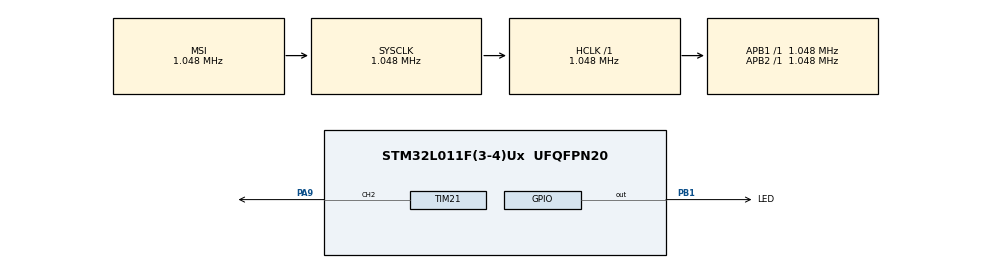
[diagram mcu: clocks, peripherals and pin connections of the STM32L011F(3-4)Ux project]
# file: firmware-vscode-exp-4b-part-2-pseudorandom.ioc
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Mcu.Family=STM32L0
Mcu.Name=STM32L011F(3-4)Ux
Mcu.Package=UFQFPN20
NVIC.TIM21_IRQn=true\:0\:0\:false\:false\:true\:true\:true\:true
NVIC.TIM2_IRQn=true\:0\:0\:false\:false\:true\:true\:true\:true
PA9.Signal=S_TIM21_CH2
PB1.GPIO_Label=LED
PB1.Signal=GPIO_Output
ProjectManager.HeapSize=0x200
ProjectManager.StackSize=0x400
ProjectManager.TargetToolchain=Makefile
RCC.AHBFreq_Value=1048000
RCC.APB1Freq_Value=1048000
RCC.APB1TimFreq_Value=1048000
RCC.APB2Freq_Value=1048000
RCC.APB2TimFreq_Value=1048000
RCC.HCLKFreq_Value=1048000
RCC.HSE_VALUE=8000000
RCC.HSI16_VALUE=16000000
RCC.HSI_VALUE=16000000
RCC.LSE_VALUE=32768
RCC.MSIClockRange=RCC_MSIRANGE_4
RCC.MSI_VALUE=1048000
RCC.SYSCLKFreq_VALUE=1048000
RCC.VCOOutputFreq_Value=48000000
SH.S_TIM21_CH2.0=TIM21_CH2,PWM Generation2 CH2
TIM2.Period=523
TIM2.Prescaler=1
TIM21.Channel-PWM\ Generation2\ CH2=TIM_CHANNEL_2
TIM21.OCMode_PWM-PWM\ Generation2\ CH2=TIM_OCMODE_PWM2
TIM21.Period=1
TIM21.Pulse-PWM\ Generation2\ CH2=1
VP_TIM21_VS_ClockSourceINT.Mode=Internal
VP_TIM2_VS_ClockSourceINT.Mode=Internal
board=custom

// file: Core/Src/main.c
/* USER CODE BEGIN Header */
/**
  ******************************************************************************
  * @file           : main.c
  * @brief          : Main program body
  ******************************************************************************
  * @attention
  *
  * Copyright (c) 2024 STMicroelectronics.
  * All rights reserved.
  *
  * This software is licensed under terms that can be found in the LICENSE file
  * in the root directory of this software component.
  * If no LICENSE file comes with this software, it is provided AS-IS.
  *
  ******************************************************************************
  */
/* USER CODE END Header */
#include "main.h"

/* USER CODE BEGIN Includes */
#include "modulator.h"

#include <stdio.h>
#include <string.h> // Include the header for memcpy

/* USER CODE END Includes */

TIM_HandleTypeDef htim2;
TIM_HandleTypeDef htim21;

/* USER CODE BEGIN PV */
bc_handler_struct bc_handler;

/* USER CODE END PV */

void SystemClock_Config(void);
static void MX_GPIO_Init(void);
static void MX_TIM2_Init(void);
static void MX_TIM21_Init(void);

/* USER CODE BEGIN 0 */

const uint8_t code [] = { //10+4096
0xAA, 0xAA, 0xAA, 0xAA, 0xAA, 0xAA, 0xAA, 0xAA, 0xAA, 0xAA, 0x0C, 0x6E, 0x53, 0x78, 0xA7, 0x69, 0x46, 0x39, 0xC8, 0xBA,
0xD7, 0x24, 0x50, 0xB0, 0x38, 0x00, 0x84, 0x8D, 0xD4, 0x2C, 0xF0, 0xE5, 0xF4, 0x43, 0x4B, 0xC3, 0xEA, 0x7A, 0xDB, 0x03,
0x24, 0x27, 0x6C, 0xC5, 0x8B, 0xD5, 0x33, 0x9A, 0xB8, 0x88, 0xFB, 0x7C, 0xA9, 0xF7, 0x7C, 0xFB, 0x4E, 0x13, 0x72, 0xA5,
0x08, 0xC3, 0xE6, 0x8D, 0xC3, 0x87, 0xC4, 0x6E, 0x25, 0xA0, 0x5E, 0x12, 0x7E, 0xA4, 0x1C, 0x38, 0xBA, 0x1A, 0xFB, 0x80,
0x78, 0x7A, 0x6F, 0xF5, 0x56, 0x72, 0x86, 0x62, 0x0C, 0xCF, 0xDB, 0x1F, 0xEF, 0x4D, 0x1A, 0x3A, 0x9E, 0x96, 0x21, 0x00,
0xCC, 0xC7, 0x23, 0x24, 0x4B, 0x62, 0x4F, 0x26, 0x77, 0x4B, 0x30, 0x90, 0x8A, 0xC4, 0xCA, 0xDD, 0xF8, 0xC5, 0xFB, 0xF5,
0x13, 0x59, 0x92, 0x03, 0xBB, 0x7E, 0x78, 0xC0, 0xE9, 0xAC, 0xB3, 0xEE, 0xD0, 0x61, 0xE2, 0x45, 0x26, 0x01, 0x84, 0x3D,
0x6C, 0x88, 0xAA, 0x42, 0x06, 0x15, 0xCB, 0xE9, 0xFF, 0x05, 0x2E, 0x0B, 0xF0, 0x47, 0x8F, 0x6A, 0x71, 0x84, 0x4B, 0x22,
0x74, 0x5C, 0xF0, 0x17, 0x7E, 0x0E, 0xAB, 0x1E, 0x41, 0xBB, 0xA3, 0x6F, 0xED, 0x4E, 0x89, 0x3D, 0x16, 0xC0, 0x07, 0xDF,
0xBD, 0xA2, 0x37, 0x32, 0xF6, 0x87, 0x07, 0x79, 0x1A, 0x02, 0x79, 0x47, 0x67, 0x88, 0xB9, 0x35, 0xCF, 0xDB, 0x87, 0x58,
0xA9, 0xE5, 0x3B, 0x0C, 0x8D, 0x1E, 0x54, 0x19, 0x0A, 0xE7, 0xD1, 0x74, 0xB3, 0x02, 0x12, 0x77, 0xC9, 0xFF, 0x16, 0xD5,
0xF8, 0x34, 0xEE, 0xC5, 0xD4, 0x60, 0x89, 0x96, 0x93, 0x53, 0x35, 0xCB, 0x2B, 0x10, 0x27, 0x9D, 0x29, 0x64, 0x2F, 0x2B,
0x51, 0x1D, 0x5C, 0xD7, 0xAF, 0x99, 0x5D, 0x02, 0xBD, 0x97, 0xB5, 0x1D, 0x82, 0x12, 0xC0, 0xDC, 0xA8, 0x09, 0x21, 0xBD,
0xB2, 0xE0, 0xFE, 0xC6, 0xD6, 0xFE, 0xBA, 0x15, 0x96, 0xF2, 0x77, 0x22, 0x1E, 0xC5, 0x90, 0xC5, 0x50, 0x86, 0xCA, 0x5C,
0x8A, 0x9D, 0x13, 0x42, 0x8A, 0x06, 0xBF, 0x25, 0x08, 0xC8, 0xDE, 0xA2, 0x5D, 0x14, 0x34, 0x2C, 0xE3, 0xD1, 0x50, 0xD3,
0xE0, 0x9D, 0x16, 0x6A, 0xA3, 0x5A, 0x12, 0x39, 0xEC, 0x6D, 0x20, 0x7C, 0x1C, 0x38, 0xBC, 0x8A, 0x8E, 0x5F, 0x62, 0x75,
0x83, 0xDB, 0x6B, 0x3F, 0x84, 0x01, 0xAC, 0x13, 0x28, 0xA8, 0x13, 0x65, 0xD0, 0x67, 0xCD, 0xEB, 0x8C, 0x14, 0x56, 0x49,
0x39, 0x15, 0xF8, 0x63, 0xB5, 0x49, 0x70, 0x8F, 0xBE, 0x5E, 0x4D, 0xC2, 0x2B, 0xA1, 0xEC, 0xBD, 0xB3, 0xDC, 0xD0, 0x7C,
0xFD, 0x33, 0xFA, 0x1F, 0x44, 0xBE, 0x1D, 0x90, 0x72, 0x89, 0x0A, 0x53, 0x90, 0x4E, 0x44, 0x57, 0x6A, 0xA6, 0x53, 0xAC,
0x4B, 0x62, 0x93, 0x2C, 0x35, 0x29, 0x3D, 0x6D, 0x0E, 0x6F, 0xAD, 0xEF, 0xCA, 0xF6, 0xA8, 0x19, 0xDB, 0x7E, 0x8A, 0x52,
0xE6, 0xA4, 0xE0, 0x22, 0x8D, 0x97, 0xE7, 0xDD, 0xE6, 0xDF, 0xAE, 0xE5, 0x92, 0x9A, 0x5D, 0xE9, 0x93, 0xE8, 0xDB, 0xCE,
0x49, 0x7C, 0xF9, 0xBD, 0xE9, 0xD3, 0x57, 0x65, 0x1C, 0x99, 0x90, 0x1C, 0x6E, 0x6E, 0xCA, 0xE4, 0x11, 0xA6, 0x81, 0x1F,
0x73, 0x7D, 0xED, 0xAE, 0x23, 0xFC, 0x4D, 0x4E, 0xF5, 0x49, 0x79, 0x5C, 0xDA, 0xAC, 0xAA, 0x97, 0x67, 0x21, 0xBF, 0xBA,
0x1C, 0x9A, 0x00, 0xE9, 0x6B, 0x3E, 0xC7, 0x52, 0xCE, 0x35, 0x09, 0x60, 0x41, 0x45, 0xC6, 0xEB, 0x25, 0xE5, 0x4F, 0x1C,
0xC3, 0x0A, 0x85, 0x46, 0x7E, 0x01, 0x8E, 0x72, 0x61, 0x0B, 0x94, 0xA0, 0x02, 0xE2, 0x95, 0x79, 0xA9, 0x94, 0xB1, 0x15,
0xCD, 0xA5, 0xBC, 0x3B, 0x9D, 0xF9, 0x07, 0x90, 0x0D, 0x90, 0x2C, 0x12, 0x49, 0xEF, 0xD5, 0x5B, 0xFD, 0xC5, 0x33, 0xFE,
0xFC, 0x5F, 0x65, 0xF3, 0xB1, 0xE0, 0xD4, 0xBD, 0xC5, 0x50, 0xEE, 0x96, 0x36, 0xF6, 0x4A, 0x3E, 0xB0, 0x8A, 0x53, 0xC7,
0x83, 0x0F, 0x70, 0x75, 0x56, 0x2D, 0xE7, 0xF5, 0x19, 0x50, 0x0F, 0x41, 0x32, 0xF2, 0x3D, 0xA5, 0x8F, 0x2A, 0xF6, 0x18,
0x4D, 0xB5, 0x54, 0xE0, 0x9F, 0x30, 0xDF, 0x31, 0x47, 0xC7, 0xE9, 0xE4, 0x3F, 0x46, 0x3C, 0x0E, 0x46, 0xD7, 0x41, 0xF0,
0x48, 0x79, 0x34, 0x46, 0x1A, 0xDE, 0xD4, 0x63, 0x0D, 0xF8, 0xEE, 0xD0, 0xC0, 0x45, 0x87, 0x51, 0x50, 0xFE, 0x07, 0xCA,
0x29, 0xE5, 0xD7, 0xF8, 0x78, 0xF0, 0x65, 0x34, 0x27, 0xF9, 0xA5, 0x4C, 0x58, 0x17, 0xAB, 0xE9, 0x81, 0xBE, 0x5A, 0x5D,
0xDF, 0x03, 0xB9, 0x7B, 0xF1, 0x4D, 0x00, 0xDF, 0xC0, 0xD0, 0x12, 0x95, 0xB9, 0x55, 0xDB, 0x22, 0x93, 0x90, 0x02, 0xF1,
0xD3, 0x8E, 0xF3, 0x5B, 0x33, 0xB9, 0xA0, 0x94, 0x6C, 0x37, 0x7F, 0x5F, 0x12, 0x55, 0x9C, 0xB8, 0xAE, 0x83, 0xAC, 0xC7,
0xFD, 0xD9, 0x73, 0xC9, 0x5D, 0xF6, 0x82, 0xD4, 0x91, 0x1D, 0x2E, 0x22, 0xB6, 0x88, 0xEB, 0xB5, 0x21, 0x6C, 0xF5, 0x3A,
0xB3, 0x38, 0x8A, 0x3C, 0xBD, 0xFE, 0xC1, 0x24, 0x1F, 0xB1, 0x63, 0xA8, 0x45, 0x43, 0x67, 0xF0, 0x27, 0x8B, 0x12, 0x34,
0xCF, 0x74, 0x4A, 0xFA, 0xB8, 0x7D, 0x1A, 0xF6, 0xA6, 0xBD, 0xCA, 0x7C, 0x05, 0xDB, 0x48, 0x77, 0xEE, 0x03, 0xFF, 0xC2,
0x20, 0x63, 0x18, 0x0F, 0x8E, 0xBB, 0xDE, 0x39, 0x11, 0xCD, 0x07, 0xCF, 0xEC, 0xC0, 0x34, 0x03, 0x1F, 0x48, 0x14, 0xD1,
0x7B, 0x6C, 0x5F, 0x1C, 0x8C, 0xF7, 0x76, 0x32, 0xB6, 0x5D, 0xA8, 0xC7, 0xD5, 0x37, 0x99, 0x37, 0x83, 0x39, 0xB3, 0x1C,
0x68, 0x40, 0x0B, 0x4F, 0x7D, 0x10, 0x39, 0x9D, 0xC9, 0x92, 0x0D, 0xE6, 0x03, 0xB7, 0x06, 0x6A, 0x2A, 0x3E, 0x96, 0xDF,
0x2B, 0xAB, 0xB3, 0x33, 0x1C, 0x81, 0x44, 0x7A, 0xC9, 0x79, 0xB9, 0x1B, 0xE8, 0xF3, 0x06, 0xF7, 0x00, 0x07, 0x97, 0x80,
0xB0, 0xEA, 0xC8, 0x6E, 0xBB, 0x21, 0xC7, 0xF5, 0xF7, 0x95, 0xB6, 0x10, 0x0C, 0x9A, 0xF1, 0xEC, 0x9C, 0x62, 0xEB, 0x5E,
0x2C, 0x76, 0xD9, 0xFF, 0xBC, 0x5A, 0xC4, 0x13, 0xAF, 0xF3, 0x17, 0xEA, 0x05, 0xA4, 0x5A, 0x0D, 0x69, 0xA3, 0x76, 0xAB,
0xAC, 0x70, 0x88, 0x4A, 0x87, 0x11, 0x64, 0x62, 0x62, 0x58, 0xDF, 0x4A, 0x3E, 0x1D, 0x1E, 0xDE, 0x5B, 0x2B, 0xD4, 0x15,
0x36, 0x75, 0x94, 0x09, 0x7E, 0x80, 0x69, 0x56, 0xBF, 0x7C, 0xB0, 0x0D, 0x36, 0x51, 0xD6, 0x34, 0x12, 0x1A, 0x6A, 0xFB,
0xED, 0xBD, 0xFF, 0x38, 0x79, 0xE6, 0x65, 0xD2, 0x4C, 0xBB, 0x04, 0xF1, 0x2B, 0x31, 0x5C, 0x33, 0x09, 0x62, 0xF8, 0xCC,
0x04, 0xE6, 0x47, 0x6A, 0x38, 0xBA, 0xAE, 0x8E, 0xFA, 0x02, 0x9D, 0x6D, 0xFD, 0x06, 0xA0, 0x50, 0x7A, 0x65, 0xCD, 0xAD,
0x3D, 0xC0, 0x33, 0x80, 0x7C, 0xF9, 0x67, 0x4F, 0x80, 0xBF, 0x7A, 0x92, 0xA4, 0x84, 0x9A, 0x07, 0x10, 0x7D, 0x82, 0x52,
0x7C, 0xB2, 0xF7, 0xAF, 0xA8, 0xC0, 0xED, 0xB8, 0x49, 0xAF, 0x5E, 0x36, 0xD5, 0x9E, 0x80, 0xAE, 0x7C, 0x14, 0x7C, 0xED,
0xEA, 0xD3, 0x41, 0xED, 0x14, 0x32, 0x69, 0xF3, 0x86, 0x58, 0x27, 0x35, 0xD7, 0x23, 0xD0, 0xAA, 0x37, 0xC2, 0xE5, 0x76,
0x8E, 0x60, 0xF0, 0xEC, 0x75, 0x66, 0xD4, 0x3D, 0x5E, 0x03, 0xB4, 0xD7, 0xBD, 0x7A, 0x3A, 0x42, 0xB6, 0xBB, 0x30, 0xC7,
0x6A, 0x4F, 0x77, 0xF1, 0xCE, 0xBA, 0x7F, 0xD9, 0x8F, 0xE5, 0x37, 0xDA, 0x58, 0xF5, 0x0E, 0x98, 0x16, 0x96, 0x55, 0xF9,
0x99, 0x8C, 0x93, 0x1D, 0xFB, 0x69, 0xFA, 0xE1, 0x63, 0xD7, 0xC9, 0x8F, 0x7E, 0xEE, 0x39, 0x63, 0xAC, 0xC8, 0xEF, 0x9A,
0x48, 0x85, 0xEE, 0x63, 0x67, 0xEF, 0x3F, 0x32, 0x11, 0xDF, 0x0C, 0x9D, 0xCE, 0x1F, 0x1E, 0x81, 0x33, 0x66, 0x39, 0x82,
0x23, 0xFC, 0x0C, 0x10, 0x52, 0xC7, 0x66, 0x79, 0x37, 0xE6, 0x7B, 0xA4, 0xF5, 0x65, 0x1F, 0x1E, 0x7A, 0xEC, 0xA7, 0xA0,
0x35, 0x6B, 0xF4, 0x01, 0x33, 0xCC, 0x53, 0x63, 0xC7, 0x1D, 0x7C, 0xC5, 0xB0, 0xCE, 0xDB, 0xCB, 0x05, 0x29, 0x2C, 0x73,
0xDC, 0x23, 0x01, 0xFC, 0x04, 0x3C, 0x1C, 0x5E, 0x38, 0xB9, 0x72, 0xE7, 0x91, 0x60, 0x0D, 0x50, 0x5C, 0xDC, 0xCE, 0xD1,
0x03, 0x37, 0x50, 0x88, 0x33, 0xEA, 0xC4, 0xDB, 0x6E, 0x64, 0x8D, 0x7F, 0xB4, 0x6B, 0x7A, 0xE8, 0xD0, 0x23, 0x87, 0x85,
0x05, 0xEF, 0xDA, 0x48, 0x45, 0x86, 0x01, 0x7F, 0xF1, 0x16, 0xAD, 0x48, 0x5B, 0x0B, 0x04, 0x32, 0xDC, 0x48, 0xD7, 0x02,
0x11, 0xF1, 0xF6, 0xD6, 0x8B, 0x54, 0x49, 0x09, 0x79, 0x0A, 0x5D, 0xC7, 0xB8, 0x6F, 0x19, 0x72, 0xD4, 0xF5, 0x12, 0xB2,
0xA7, 0xBC, 0xD6, 0xA2, 0xAE, 0x28, 0xC2, 0x8D, 0x09, 0xC6, 0x4E, 0x17, 0x2A, 0x9E, 0x5A, 0x75, 0x00, 0xFC, 0x6E, 0xE0,
0x89, 0xAA, 0x85, 0x2A, 0xA8, 0x29, 0xB7, 0x43, 0x5A, 0xF9, 0x30, 0x0A, 0xA2, 0x80, 0x68, 0xF9, 0x34, 0xD3, 0x8B, 0xBC,
0x88, 0x30, 0x55, 0x08, 0xDC, 0x26, 0xB6, 0x1F, 0xB0, 0x34, 0xF6, 0x2D, 0x56, 0x01, 0x45, 0xBF, 0x17, 0x56, 0x2B, 0xF8,
0xCC, 0x7A, 0x29, 0x50, 0x69, 0x25, 0x55, 0xFB, 0x3B, 0xDA, 0x9E, 0x0D, 0x2E, 0x60, 0xEC, 0xAC, 0x2D, 0xBF, 0x3F, 0x0D,
0x03, 0xF2, 0x4F, 0xA1, 0x2B, 0x25, 0xF0, 0x90, 0x64, 0x5C, 0x8A, 0x45, 0x62, 0x03, 0x6E, 0xFF, 0x6E, 0xF6, 0xE7, 0x30,
0xE9, 0xF7, 0xAC, 0x2A, 0x26, 0x83, 0x46, 0x37, 0x37, 0x84, 0xD2, 0x52, 0x00, 0x44, 0x1F, 0xEE, 0xB5, 0x85, 0xFC, 0x5C,
0xE9, 0x4E, 0x4E, 0xB4, 0x55, 0xE4, 0x83, 0x5C, 0xE5, 0x52, 0x75, 0x4E, 0x4C, 0x4B, 0x76, 0xC0, 0xBB, 0x6E, 0x6B, 0xAD,
0x40, 0x58, 0x85, 0xF9, 0xEF, 0xAD, 0x5C, 0xCA, 0xBF, 0x92, 0xF6, 0x36, 0x16, 0x9B, 0x76, 0x3C, 0xC7, 0x83, 0xDB, 0xBB,
0xD6, 0x6F, 0xB0, 0x8C, 0xB7, 0x02, 0x91, 0xBB, 0x6E, 0xBD, 0xE1, 0x06, 0x68, 0x2C, 0xDC, 0x99, 0x78, 0x2A, 0xEA, 0x6E,
0x2E, 0xC0, 0xF8, 0xA2, 0x32, 0xFB, 0x0A, 0xCA, 0x89, 0x2D, 0x7A, 0xD0, 0xEA, 0x02, 0x3B, 0x84, 0xDE, 0x3C, 0x48, 0x16,
0xDE, 0x78, 0x09, 0x5F, 0x55, 0xA4, 0xFD, 0x53, 0x07, 0xF6, 0x2E, 0x8D, 0x67, 0x65, 0x4A, 0x17, 0xCF, 0xF7, 0xE9, 0x22,
0x76, 0xA5, 0x1C, 0x93, 0x60, 0x0F, 0xB2, 0xF5, 0xEE, 0xD4, 0xA8, 0x9A, 0x61, 0xFB, 0xD9, 0xDA, 0xC8, 0x5D, 0xA2, 0xB1,
0x05, 0x5C, 0x27, 0x85, 0xB0, 0x3A, 0xFE, 0x73, 0xE6, 0xD5, 0x9A, 0x96, 0x15, 0x30, 0xBC, 0xE6, 0x5A, 0x30, 0x84, 0xEC,
0x3C, 0x94, 0xD3, 0xCA, 0x8E, 0xCC, 0x2E, 0x19, 0x68, 0x06, 0x15, 0xE7, 0x0B, 0x74, 0x5D, 0xE6, 0x76, 0x23, 0x75, 0x52,
0x9F, 0x1E, 0xBA, 0xD9, 0x8A, 0x9C, 0xFF, 0x9E, 0x03, 0xE4, 0x2C, 0x82, 0x93, 0xA9, 0x37, 0x86, 0xDA, 0x4C, 0x3A, 0x4B,
0xD9, 0x1C, 0xF9, 0x96, 0x71, 0x67, 0xEE, 0xC4, 0x22, 0x47, 0x89, 0x5E, 0xCC, 0xEB, 0x24, 0x74, 0xC4, 0xAF, 0x00, 0x3F,
0x77, 0xCE, 0xD9, 0x63, 0x55, 0xA5, 0x06, 0x5C, 0x8E, 0x8F, 0xEB, 0x1F, 0x32, 0xCA, 0xF0, 0x8C, 0x19, 0x9A, 0xF1, 0x5E,
0xBC, 0x11, 0x72, 0x07, 0xF3, 0x6D, 0x44, 0x4C, 0xB6, 0xE1, 0xFB, 0xCF, 0x7A, 0x6A, 0x6B, 0xBA, 0x86, 0xCC, 0x08, 0x62,
0x41, 0x02, 0x05, 0x58, 0xC4, 0x16, 0x9A, 0xD1, 0xAA, 0x7E, 0xAB, 0xE9, 0x7E, 0xCE, 0x8F, 0xF5, 0x7D, 0x8B, 0x4D, 0x24,
0xEB, 0x39, 0xD9, 0x5C, 0xAE, 0x5C, 0xF6, 0x60, 0x6A, 0xFE, 0x72, 0x1A, 0x6B, 0x0A, 0xBD, 0x0D, 0x64, 0x9F, 0x90, 0xA0,
0x4E, 0xDC, 0xCD, 0xC3, 0x9D, 0xB4, 0xDB, 0x09, 0x61, 0xB5, 0x87, 0xF2, 0x12, 0x2A, 0x20, 0xBE, 0x8A, 0xCF, 0x4C, 0xE6,
0xF2, 0x84, 0x13, 0xDB, 0xFD, 0xB5, 0x9E, 0x94, 0xFD, 0xE3, 0xF9, 0xB4, 0x4D, 0x1A, 0x5E, 0x1F, 0xC5, 0x51, 0x5E, 0x8D,
0x64, 0x11, 0xCF, 0x9B, 0x2A, 0x83, 0xC5, 0x45, 0x57, 0x3A, 0x72, 0x68, 0x0E, 0x8D, 0xC8, 0x67, 0x42, 0x7B, 0x70, 0xEB,
0x76, 0xB1, 0xBC, 0x2A, 0x9E, 0x1F, 0xC9, 0x4E, 0x41, 0x30, 0x82, 0x3F, 0xB0, 0x2C, 0xF0, 0xB9, 0x43, 0x8F, 0xBC, 0x3D,
0x7C, 0x69, 0x25, 0xFD, 0xA7, 0x40, 0x98, 0xFA, 0x4B, 0x70, 0xFA, 0x8D, 0x52, 0xE8, 0x62, 0x6E, 0xD7, 0xDB, 0x00, 0x53,
0xBF, 0x94, 0x2A, 0xBD, 0x7B, 0xCA, 0xE5, 0x20, 0xE3, 0xB6, 0xB0, 0xA2, 0x45, 0x67, 0x12, 0x14, 0x5D, 0xDF, 0x0F, 0xAC,
0xF6, 0x09, 0xA2, 0x24, 0xFA, 0xE3, 0x4E, 0x64, 0x45, 0x2C, 0xE3, 0x67, 0x09, 0x67, 0xD5, 0x7B, 0x9D, 0xC3, 0xF4, 0xBC,
0x4B, 0x20, 0x0C, 0x9A, 0x95, 0xB1, 0x08, 0xA1, 0x2B, 0x83, 0xF7, 0xA8, 0x70, 0x9E, 0x7D, 0x97, 0xC7, 0x74, 0xA1, 0xF5,
0xDC, 0x16, 0x5E, 0xA6, 0x74, 0xB6, 0xAF, 0x87, 0xFE, 0x80, 0x4B, 0xAA, 0xC2, 0xBF, 0x87, 0xB9, 0xAA, 0xAF, 0x48, 0x8E,
0x19, 0x32, 0xA0, 0x0B, 0x25, 0xC9, 0x0B, 0xE8, 0xC1, 0x2D, 0x72, 0x8C, 0x6B, 0x94, 0x96, 0x9F, 0xF7, 0x0D, 0x3A, 0x68,
0x11, 0x8D, 0x3C, 0xD4, 0x8B, 0xCC, 0x41, 0xB3, 0x8A, 0x2E, 0x0C, 0xAF, 0x99, 0x6F, 0xCB, 0x1B, 0x48, 0x8D, 0x29, 0xF1,
0x42, 0x8D, 0xB1, 0xD6, 0x9C, 0x50, 0x96, 0xB6, 0xF3, 0x26, 0xB8, 0xDF, 0x92, 0x7A, 0x1C, 0xAB, 0x6A, 0xAE, 0x43, 0x36,
0x01, 0x05, 0xFD, 0x22, 0x1D, 0x1E, 0xFD, 0x04, 0x1C, 0x74, 0xB1, 0x54, 0x31, 0x34, 0xFB, 0x47, 0xD1, 0x26, 0x52, 0x6E,
0x8A, 0xC6, 0xFA, 0x00, 0xBF, 0x07, 0xDD, 0x59, 0x18, 0xC2, 0xD6, 0x5F, 0x74, 0x94, 0x0A, 0xCF, 0xB3, 0xBF, 0x00, 0xBB,
0x83, 0xFF, 0x7A, 0x86, 0x2F, 0xFC, 0xB3, 0x14, 0x14, 0x2E, 0x84, 0x95, 0x85, 0xBC, 0x5F, 0xAD, 0x83, 0x77, 0x29, 0xCF,
0x85, 0x2C, 0x65, 0x06, 0x72, 0x84, 0x87, 0xB5, 0xB7, 0xA9, 0x3C, 0x15, 0xFA, 0x73, 0xB1, 0x9F, 0x15, 0x99, 0xEC, 0xC1,
0x6E, 0x7F, 0x23, 0x4D, 0x1D, 0xD9, 0x0B, 0xD9, 0x26, 0xAC, 0x42, 0x11, 0xF8, 0x54, 0x62, 0xEC, 0xF1, 0xD8, 0xB3, 0xD0,
0xC4, 0x39, 0xDD, 0x20, 0xF6, 0x75, 0x9F, 0x18, 0xEA, 0x0C, 0x6D, 0xDC, 0x5A, 0xD7, 0xFD, 0x1E, 0x2A, 0x60, 0x74, 0x98,
0x3D, 0x55, 0x43, 0x00, 0x8F, 0xB1, 0x37, 0xA4, 0x4A, 0x09, 0x67, 0x89, 0x43, 0x17, 0xEE, 0x5B, 0x5F, 0x05, 0xBF, 0x60,
0x2C, 0xAF, 0xD3, 0x4D, 0x30, 0x24, 0x7D, 0xB2, 0xB3, 0x0E, 0x3C, 0xAE, 0x9C, 0x76, 0x41, 0xBB, 0x8A, 0xA1, 0x03, 0x42,
0xFC, 0x90, 0x31, 0x80, 0xAD, 0x14, 0x3F, 0x97, 0x76, 0x40, 0x02, 0x53, 0x8F, 0xD2, 0x70, 0x59, 0xBA, 0x0E, 0xDE, 0x7F,
0xE0, 0x19, 0xDF, 0x85, 0xDD, 0xC5, 0x19, 0x02, 0x7D, 0xF7, 0xE1, 0xAB, 0x26, 0xDF, 0xA8, 0x26, 0x4E, 0x5B, 0x8C, 0x1D,
0x6C, 0x4F, 0xC6, 0xA3, 0x4B, 0x45, 0xBB, 0x02, 0x49, 0x18, 0x0C, 0x0F, 0xA7, 0x3A, 0x03, 0x0E, 0x37, 0xAB, 0xDE, 0x26,
0x00, 0x25, 0x59, 0xDF, 0xC3, 0xC1, 0xE3, 0xE9, 0xA2, 0x2C, 0xA4, 0x7D, 0x88, 0xB9, 0x74, 0xAF, 0xCF, 0x60, 0xFB, 0x24,
0x61, 0xC2, 0xE7, 0x19, 0xD9, 0x7C, 0x77, 0x34, 0x91, 0xEB, 0x06, 0xD4, 0x29, 0x4B, 0x56, 0x6A, 0x65, 0xBC, 0x5C, 0xF1,
0xD0, 0x56, 0xD1, 0x8D, 0x53, 0x63, 0x61, 0x77, 0xEA, 0x7D, 0x96, 0x8F, 0xAA, 0x17, 0xE2, 0x3B, 0x1F, 0xBD, 0xC0, 0xED,
0x96, 0xF7, 0xC5, 0x54, 0x9B, 0x06, 0x92, 0xB0, 0xCE, 0x3F, 0xA9, 0x4B, 0xD0, 0xED, 0x63, 0x59, 0x18, 0xA8, 0x83, 0x11,
0x7D, 0xBD, 0x4F, 0x95, 0x45, 0x9A, 0x95, 0x9F, 0x07, 0x68, 0x49, 0x98, 0x07, 0x86, 0x5D, 0x3C, 0x8D, 0x4A, 0xD7, 0x08,
0x77, 0x97, 0x27, 0x6F, 0x45, 0xFF, 0xC0, 0x18, 0x0F, 0x54, 0x0F, 0x7A, 0x11, 0x6E, 0x9F, 0x10, 0x55, 0x22, 0x16, 0xA6,
0x6E, 0x77, 0x56, 0x11, 0x9D, 0xCA, 0x68, 0x46, 0x1C, 0x47, 0x67, 0x07, 0xFA, 0x87, 0x4C, 0x7B, 0x67, 0x18, 0x6E, 0x37,
0xA6, 0x85, 0x3D, 0x9B, 0xF0, 0x12, 0x93, 0xD3, 0xBC, 0xCF, 0x1D, 0x3D, 0xB4, 0x21, 0x83, 0x90, 0x75, 0x2D, 0x58, 0x94,
0x54, 0xA0, 0xB3, 0x14, 0x2D, 0x08, 0x12, 0xCD, 0xD3, 0x77, 0xDB, 0x6A, 0xAA, 0xEA, 0x04, 0xD0, 0x6F, 0xC0, 0x85, 0x90,
0x9D, 0x93, 0x46, 0x35, 0x46, 0x91, 0x0E, 0xF1, 0xE8, 0x9C, 0xF8, 0x87, 0xB7, 0x3E, 0x83, 0x25, 0x52, 0x2C, 0x60, 0x9C,
0xAF, 0x05, 0x1B, 0x80, 0x9D, 0xD8, 0x4D, 0xC0, 0x10, 0xB3, 0x1D, 0xEB, 0xE6, 0xAC, 0xE1, 0x9B, 0x96, 0x44, 0x6B, 0xD0,
0x3F, 0x5C, 0xD3, 0x2B, 0xFB, 0xAF, 0xA8, 0x43, 0x9E, 0xDC, 0x71, 0xA7, 0xCF, 0x0B, 0x72, 0x4F, 0xFA, 0x5F, 0xFA, 0xC7,
0x28, 0x6A, 0xEC, 0x6B, 0x02, 0x0E, 0x48, 0xDF, 0x44, 0xFA, 0xD6, 0x1B, 0x42, 0xF9, 0x57, 0x9D, 0x50, 0x53, 0xDD, 0xE3,
0x5B, 0x56, 0xD6, 0x74, 0x1B, 0x94, 0xC6, 0x70, 0x36, 0x7A, 0xBB, 0x48, 0xEE, 0x81, 0xD4, 0x1B, 0x1B, 0xC7, 0x2D, 0x51,
0x6B, 0x0C, 0xB2, 0x36, 0xD6, 0x7C, 0xFE, 0x4E, 0x41, 0x1D, 0x09, 0xA8, 0xC9, 0x86, 0x0B, 0x9E, 0xDD, 0x8E, 0xE0, 0x68,
0x28, 0x3E, 0xAC, 0xBD, 0xCE, 0x7F, 0x5C, 0x39, 0x53, 0x53, 0xE8, 0xE6, 0x27, 0xA5, 0xEA, 0xE9, 0x6A, 0xEE, 0xD5, 0x14,
0x45, 0xEB, 0x00, 0x04, 0x4B, 0xB0, 0x65, 0x71, 0x84, 0xDB, 0x31, 0xA1, 0x32, 0x53, 0xD9, 0xC8, 0x4A, 0x9E, 0x66, 0x29,
0x94, 0x08, 0x8D, 0x83, 0x67, 0x73, 0x15, 0xD9, 0x34, 0x36, 0x3C, 0xA5, 0x40, 0xC7, 0x27, 0x68, 0x1C, 0x2A, 0xBA, 0x92,
0x88, 0x08, 0xFB, 0x74, 0x59, 0x89, 0x16, 0x7C, 0xFD, 0x64, 0xAC, 0x3A, 0x9A, 0x77, 0xDD, 0xDC, 0x83, 0x1E, 0x28, 0x16,
0xCA, 0x9B, 0x19, 0x19, 0xF7, 0xE5, 0x51, 0x7E, 0x40, 0x4C, 0xDD, 0x84, 0x85, 0xF6, 0xCE, 0xF9, 0xEF, 0x56, 0x2E, 0xC7,
0x3B, 0x20, 0x21, 0xA1, 0xB6, 0x85, 0x51, 0x9A, 0x3A, 0xE9, 0xD6, 0x98, 0x2A, 0x6C, 0xC1, 0x06, 0x6C, 0x8C, 0xE4, 0x4D,
0x4D, 0xF3, 0x6F, 0x18, 0xC7, 0x35, 0xBA, 0x2A, 0xE1, 0xC3, 0xE3, 0x6C, 0x7F, 0x0D, 0x03, 0xFA, 0xE7, 0x70, 0x59, 0x17,
0x62, 0xD9, 0x80, 0x1A, 0xAC, 0xA7, 0x7F, 0x9C, 0x7E, 0xF7, 0x4D, 0xF0, 0x45, 0xEA, 0xD1, 0xC9, 0x4C, 0xCE, 0x90, 0xC5,
0x17, 0xE6, 0x08, 0xC0, 0x7E, 0xCA, 0x3C, 0xE2, 0xC3, 0xCF, 0xB5, 0xC9, 0x34, 0x9A, 0x4D, 0x6F, 0x7C, 0x67, 0x66, 0x6D,
0x2C, 0x7F, 0xFD, 0xB3, 0x83, 0xD4, 0x91, 0x1F, 0x18, 0x22, 0xD4, 0x13, 0xD2, 0x4B, 0xFC, 0x1B, 0x2D, 0xE9, 0x17, 0x17,
0x82, 0x41, 0x2A, 0xAC, 0x89, 0x0C, 0xF3, 0x27, 0x35, 0x24, 0xA2, 0xAE, 0x38, 0x10, 0x6B, 0xFF, 0xD6, 0x4E, 0x74, 0x90,
0x61, 0x80, 0x2C, 0x3D, 0xA3, 0x36, 0xA4, 0x07, 0x47, 0xB6, 0x25, 0xA0, 0x02, 0x62, 0x7C, 0x6C, 0xE5, 0x99, 0xE6, 0xFC,
0x26, 0x45, 0x65, 0xA4, 0xD3, 0x82, 0xD6, 0x62, 0xF4, 0x26, 0xFF, 0x6E, 0x02, 0xF2, 0x2B, 0xDC, 0x86, 0xA4, 0xE1, 0x2A,
0x2E, 0x0A, 0x06, 0x4D, 0x41, 0x90, 0x6D, 0x1D, 0xE5, 0xFD, 0xEB, 0xE9, 0x58, 0x6C, 0xA2, 0xE1, 0xFC, 0x5D, 0x0A, 0x4D,
0x2B, 0xAF, 0x2D, 0x96, 0x63, 0xB1, 0xCD, 0xA9, 0x11, 0xA4, 0xA7, 0x2D, 0xDC, 0xC4, 0xE0, 0x6C, 0x09, 0x44, 0x1B, 0x6E,
0x03, 0x8E, 0x6B, 0xAB, 0x66, 0x5B, 0x8A, 0x29, 0x70, 0xB0, 0x53, 0x74, 0x27, 0x23, 0x26, 0x6B, 0x9C, 0x97, 0xF3, 0xDD,
0x86, 0x5B, 0x19, 0x65, 0xA4, 0x53, 0x4F, 0x91, 0xE5, 0x61, 0x45, 0x89, 0x1F, 0x41, 0x8E, 0x3C, 0x38, 0xC1, 0x18, 0x89,
0x90, 0x2E, 0x18, 0x6A, 0xFA, 0xF3, 0xDB, 0x0E, 0xE9, 0x6A, 0x8E, 0x50, 0x59, 0xAE, 0xDB, 0xDA, 0x2E, 0xFE, 0xBB, 0x1C,
0x09, 0x33, 0x80, 0x78, 0x9C, 0x82, 0x2B, 0x38, 0x3B, 0xBC, 0x0B, 0x44, 0x14, 0x76, 0xE7, 0x18, 0x2D, 0x0C, 0xC7, 0x70,
0xE8, 0x80, 0x3C, 0x38, 0x6E, 0xD4, 0xE4, 0x16, 0x88, 0x28, 0x2A, 0xF3, 0x0D, 0xA7, 0xEA, 0xE5, 0x58, 0x75, 0x8E, 0x76,
0xD9, 0x9C, 0x08, 0xF2, 0xF1, 0xF7, 0x84, 0x8F, 0xAD, 0xBA, 0xDE, 0xCD, 0xD3, 0x3D, 0x06, 0xFA, 0x9C, 0x1C, 0xB2, 0xB5,
0x69, 0x37, 0xED, 0xDD, 0xAF, 0x4F, 0xBC, 0x35, 0xC1, 0x47, 0x13, 0x69, 0xE6, 0x20, 0x50, 0xEE, 0x3E, 0xA0, 0x72, 0x21,
0x1E, 0x49, 0x9D, 0x68, 0x30, 0x07, 0x90, 0x75, 0x1B, 0x6C, 0x1A, 0xCE, 0x47, 0x94, 0xC8, 0xA7, 0xA7, 0x88, 0x67, 0x2A,
0x54, 0xF3, 0x2E, 0xDF, 0x00, 0x60, 0xB5, 0x74, 0xED, 0x6D, 0xE5, 0x46, 0xC6, 0x9F, 0x87, 0x4E, 0x89, 0x7C, 0x5D, 0x45,
0x88, 0x79, 0xA0, 0xA3, 0x7E, 0x5C, 0x5C, 0x42, 0x39, 0x2D, 0x81, 0x4B, 0x01, 0x33, 0x13, 0x04, 0x73, 0xA5, 0x46, 0x87,
0x59, 0x72, 0x96, 0x90, 0xEB, 0x40, 0xB5, 0xC4, 0xFA, 0x0F, 0xD7, 0x84, 0x83, 0x48, 0x42, 0x33, 0x80, 0xFC, 0xAA, 0xBA,
0x0E, 0xE4, 0xD8, 0xC6, 0xD2, 0xF2, 0x61, 0xC3, 0x47, 0x06, 0x99, 0x3F, 0xD5, 0x4F, 0xF8, 0x8A, 0xC0, 0x60, 0x7A, 0x67,
0xBB, 0x0E, 0x0B, 0x7B, 0xB9, 0x76, 0x7C, 0xAC, 0x86, 0x6F, 0x8E, 0x01, 0xD4, 0xE9, 0xD5, 0x9C, 0x3B, 0x68, 0x10, 0xA0,
0xC7, 0xE3, 0x27, 0x66, 0x58, 0xDE, 0xF0, 0xC8, 0xE9, 0xB0, 0x40, 0x63, 0xDF, 0x61, 0xA8, 0x7E, 0x30, 0x49, 0xD1, 0x38,
0x51, 0xF2, 0xA5, 0x47, 0x9C, 0x80, 0x46, 0x6A, 0x10, 0xC2, 0xB9, 0x61, 0xFD, 0x89, 0xD1, 0xCF, 0xD0, 0xA2, 0x06, 0x1B,
0x45, 0xAA, 0x39, 0xAB, 0x48, 0x0E, 0xE3, 0x96, 0xED, 0x4B, 0xC2, 0x06, 0x25, 0x72, 0xB0, 0xCD, 0xE6, 0x72, 0x49, 0x19,
0x78, 0x3F, 0x04, 0xA4, 0xBF, 0xE8, 0x1D, 0xCD, 0xA5, 0x29, 0x98, 0xDC, 0x96, 0xCD, 0x76, 0x2A, 0xAC, 0xA6, 0x16, 0x66,
0xDE, 0x51, 0x9F, 0x86, 0x50, 0x88, 0xB9, 0x7C, 0x99, 0x9E, 0xA6, 0xEF, 0xA8, 0x8D, 0x44, 0xCB, 0x01, 0x67, 0x0C, 0xA6,
0x37, 0xB2, 0x3F, 0x38, 0x85, 0xDD, 0x42, 0x73, 0xB4, 0x2A, 0x66, 0x1D, 0xEC, 0x70, 0x23, 0xAC, 0xF8, 0xDD, 0xD9, 0xAB,
0x0B, 0x84, 0xC5, 0x06, 0x22, 0x9F, 0xBA, 0x59, 0x6C, 0xE2, 0x5A, 0xC0, 0x88, 0x4D, 0xDF, 0xB8, 0x4A, 0x94, 0x30, 0x74,
0x3E, 0xD4, 0x1A, 0x46, 0x80, 0x40, 0x76, 0x78, 0x34, 0x4D, 0x40, 0x12, 0x3E, 0x43, 0xBA, 0x84, 0x4A, 0xA2, 0xA4, 0x8B,
0x41, 0x6D, 0xB1, 0x47, 0xF9, 0x31, 0x05, 0x43, 0x5C, 0xDA, 0x4B, 0x10, 0x62, 0x22, 0x4B, 0x61, 0x93, 0x3E, 0x9F, 0x97,
0x1F, 0x40, 0x96, 0x61, 0x4B, 0xDE, 0x60, 0x77, 0xAD, 0x97, 0x37, 0x27, 0x42, 0xF0, 0x7B, 0x40, 0x51, 0xF0, 0xF8, 0x93,
0xCA, 0x1B, 0xD3, 0x25, 0x15, 0xCF, 0xF9, 0xBC, 0x56, 0x3C, 0xDA, 0xC1, 0xCA, 0x5B, 0x89, 0x2F, 0x11, 0x78, 0xC8, 0x46,
0xCF, 0x98, 0xDB, 0x48, 0xEF, 0x21, 0xD2, 0xCC, 0x24, 0x82, 0xEC, 0xB1, 0x75, 0xDE, 0xEE, 0x34, 0xDF, 0x39, 0x54, 0x8E,
0x85, 0xEB, 0x42, 0x41, 0x8E, 0x51, 0x91, 0x82, 0x26, 0x08, 0xF1, 0xC5, 0xFE, 0x48, 0x6D, 0xC6, 0x77, 0x63, 0x18, 0x09,
0x00, 0xCD, 0xF0, 0x16, 0xE0, 0xC9, 0xB0, 0x48, 0x43, 0x99, 0x86, 0x8E, 0xD2, 0xA0, 0xF6, 0x50, 0x42, 0xD8, 0x68, 0x4A,
0x96, 0x04, 0x6A, 0x09, 0x76, 0xAB, 0x75, 0x84, 0xA0, 0x2C, 0x53, 0x32, 0x46, 0x94, 0xF2, 0x88, 0xBA, 0xC8, 0x7F, 0x21,
0x6B, 0x41, 0xBF, 0x51, 0xD7, 0x1D, 0x66, 0xA1, 0xE0, 0x5E, 0x8F, 0xDF, 0x21, 0x04, 0x18, 0x6C, 0xD3, 0x60, 0x2A, 0x5C,
0x87, 0xD4, 0x3E, 0x50, 0xB1, 0xE6, 0xFE, 0x8E, 0xAC, 0x19, 0xF5, 0x00, 0x13, 0x12, 0xEC, 0xB8, 0x78, 0x2D, 0x5F, 0xAF,
0x0F, 0x0A, 0x13, 0xFD, 0x3D, 0x3D, 0x26, 0x9C, 0x1D, 0x33, 0xF0, 0x4B, 0xA8, 0xA6, 0x3D, 0xA5, 0xA8, 0x79, 0xA7, 0xF2,
0xCD, 0x96, 0x30, 0xA7, 0xB4, 0xB4, 0x42, 0x68, 0x23, 0x3D, 0x30, 0x9E, 0x06, 0xE1, 0x0E, 0xAA, 0x72, 0xAD, 0x64, 0xE0,
0x6F, 0x41, 0x55, 0x9C, 0xA2, 0xEF, 0x96, 0x30, 0xD4, 0x0A, 0xB0, 0x35, 0x1C, 0x72, 0x61, 0x51, 0x2B, 0x7A, 0x09, 0xE8,
0x2B, 0x92, 0x14, 0xEF, 0x7D, 0x3C, 0x03, 0xE9, 0xEB, 0xE6, 0xF4, 0xB6, 0xC1, 0x39, 0x9F, 0xD8, 0xFF, 0x71, 0xA4, 0xED,
0x03, 0xF5, 0x1D, 0xCD, 0xDD, 0x3C, 0xD9, 0x0D, 0xFF, 0x1A, 0x0B, 0x61, 0xF9, 0xAC, 0xAC, 0x9C, 0x97, 0x8B, 0xB5, 0x77,
0x8D, 0x5C, 0xBC, 0x55, 0x7D, 0xAB, 0x37, 0xD8, 0xFF, 0x7C, 0x60, 0xBE, 0x3E, 0x60, 0xAE, 0xD0, 0x00, 0xFB, 0x9E, 0xF2,
0x0B, 0xBB, 0xD2, 0x2F, 0xBA, 0x03, 0xF2, 0x65, 0x5C, 0x44, 0xAE, 0xF9, 0xB0, 0x3C, 0xBF, 0x83, 0x73, 0x39, 0xE2, 0x11,
0xE4, 0xA9, 0x79, 0x32, 0xA8, 0x90, 0x2F, 0xAC, 0xD3, 0x58, 0x71, 0x20, 0x93, 0xF6, 0x65, 0x6E, 0x17, 0x02, 0x0F, 0x89,
0x99, 0x8C, 0x74, 0xE2, 0x1F, 0x13, 0x03, 0x41, 0x06, 0x9C, 0x4B, 0xE8, 0x99, 0xE1, 0xF5, 0x79, 0xD7, 0xAF, 0x88, 0x47,
0x5B, 0x03, 0x7B, 0x84, 0xE2, 0x18, 0xAB, 0xB7, 0x36, 0x18, 0x8D, 0x6E, 0x77, 0x3C, 0x0F, 0x01, 0x8B, 0x91, 0x0E, 0x8A,
0x01, 0x39, 0xA0, 0xDA, 0x29, 0xB2, 0xD8, 0xB6, 0xC9, 0xCD, 0xC6, 0x9B, 0xE8, 0xA0, 0xA7, 0x67, 0xFF, 0x5D, 0x66, 0x8C,
0xF9, 0xD1, 0xDA, 0x03, 0x22, 0xC4, 0x54, 0xBA, 0xA6, 0x53, 0x66, 0xF1, 0xAC, 0x69, 0x29, 0xD4, 0x56, 0x06, 0x50, 0x7D,
0xC3, 0xFB, 0x63, 0x02, 0x14, 0xE6, 0xDC, 0xD6, 0xCC, 0x76, 0x2F, 0x36, 0x6D, 0xA3, 0x15, 0xDA, 0xE3, 0x7F, 0x83, 0x75,
0x25, 0x19, 0x6D, 0x59, 0x66, 0xCB, 0xB4, 0x5B, 0x06, 0x2B, 0x04, 0x95, 0xB4, 0x71, 0x27, 0xE0, 0xB5, 0xC2, 0x15, 0xB6,
0xD5, 0xFC, 0xCE, 0xF5, 0x5B, 0x65, 0x5E, 0x2F, 0x4D, 0x49, 0x57, 0x9D, 0x3F, 0xE1, 0xD8, 0xD5, 0xF9, 0x30, 0xD2, 0x1A,
0x41, 0x87, 0xEC, 0x96, 0xA1, 0xB8, 0xEA, 0xEE, 0xAC, 0xFC, 0x9A, 0x13, 0x15, 0x5E, 0xFD, 0x4E, 0xEB, 0x4B, 0xB6, 0x78,
0x32, 0xF2, 0x6C, 0xC7, 0xB6, 0x8E, 0xDC, 0x08, 0x59, 0xBE, 0x50, 0x64, 0x3E, 0x72, 0xFB, 0xC5, 0x3F, 0xE4, 0xB2, 0x09,
0x13, 0x3A, 0x63, 0x44, 0x18, 0x21, 0x49, 0x89, 0x97, 0x9E, 0x1E, 0x6B, 0xDF, 0x89, 0x0D, 0xBB, 0x80, 0x83, 0xAE, 0xE5,
0xA8, 0x40, 0xF7, 0x2D, 0x29, 0xE9, 0x77, 0x03, 0xF3, 0x09, 0xB4, 0xBE, 0x11, 0x9A, 0x3A, 0x18, 0xBE, 0x42, 0x7B, 0x15,
0x3A, 0x97, 0x8F, 0x05, 0xF5, 0xD4, 0x5F, 0xE2, 0x06, 0xA7, 0xAD, 0x87, 0x00, 0xF7, 0x24, 0x3C, 0x19, 0x4E, 0xCF, 0x0E,
0x30, 0xE2, 0xD4, 0x26, 0xFE, 0x89, 0xE6, 0xEC, 0xB2, 0x60, 0xF5, 0x78, 0x7B, 0x73, 0x78, 0x7E, 0xB2, 0x04, 0x23, 0xAA,
0xD8, 0x36, 0x66, 0x18, 0xBD, 0x6E, 0x76, 0xF0, 0x91, 0xC8, 0x2B, 0xF3, 0x99, 0x9F, 0xC3, 0xE8, 0x2B, 0xB6, 0xDC, 0x39,
0xDC, 0xA1, 0x0C, 0xA1, 0x2A, 0x84, 0xC2, 0x7C, 0x3C, 0xDC, 0x80, 0x68, 0x51, 0x1B, 0xB6, 0x5F, 0xDF, 0x2C, 0xC9, 0xE8,
0x8B, 0xD4, 0x41, 0x0F, 0x85, 0xB6, 0xBE, 0x87, 0x0A, 0xA2, 0x7B, 0xF9, 0x98, 0x7A, 0x76, 0x23, 0xE6, 0xA6, 0x92, 0x34,
0x5A, 0xC4, 0x31, 0xFE, 0x89, 0xC2, 0xD3, 0x54, 0xB5, 0xEF, 0xAC, 0xF5, 0xCE, 0x91, 0xBE, 0xB5, 0x4D, 0x2F, 0x16, 0xFF,
0x3E, 0x38, 0x6D, 0xAA, 0xEA, 0x11, 0xE1, 0xE4, 0xD1, 0xEA, 0x72, 0xB5, 0x29, 0x44, 0x4A, 0x65, 0xA7, 0x8C, 0xD1, 0x2D,
0xDC, 0x91, 0xE2, 0xDB, 0xD7, 0xA4, 0xB1, 0x13, 0xCA, 0x1A, 0xEE, 0xC0, 0x6D, 0x97, 0x9A, 0x6C, 0x3A, 0x73, 0x65, 0x8F,
0x7F, 0xE0, 0x7C, 0xDE, 0xE1, 0xB9, 0x3F, 0x23, 0x5D, 0x89, 0x1E, 0x31, 0x96, 0x92, 0x29, 0x2D, 0x4E, 0xBB, 0xB3, 0x08,
0x4A, 0x23, 0xD8, 0x71, 0x4A, 0xC3, 0x59, 0xC5, 0xB1, 0xD2, 0xFF, 0x61, 0x4F, 0xFE, 0x72, 0x99, 0x57, 0x3F, 0xBB, 0xF3,
0x1F, 0x77, 0x78, 0x0F, 0x95, 0x4F, 0x40, 0xEB, 0x20, 0x75, 0x12, 0x19, 0x86, 0x25, 0xE7, 0x9B, 0x7A, 0x0B, 0x85, 0x77,
0x9E, 0x9B, 0xFC, 0xE7, 0x16, 0x97, 0x4C, 0x0B, 0xF4, 0xF6, 0x2E, 0x68, 0x9B, 0x92, 0x9E, 0xFA, 0x28, 0xDF, 0x84, 0x7A,
0xE9, 0xBA, 0x35, 0x25, 0x6A, 0xB4, 0x45, 0x16, 0x02, 0xD4, 0x41, 0xA3, 0x95, 0x09, 0x89, 0xC2, 0x60, 0x4C, 0x25, 0x46,
0xA2, 0x59, 0xA9, 0xD2, 0xCC, 0x80, 0x02, 0x91, 0xD3, 0x74, 0x19, 0xAC, 0x12, 0x7E, 0xE4, 0x80, 0x41, 0xF7, 0xE2, 0x5B,
0xC6, 0xE3, 0xA3, 0x7B, 0x3A, 0xD4, 0x4B, 0x4F, 0x8E, 0x42, 0xF8, 0xE2, 0x6E, 0xC4, 0xBE, 0x89, 0xBB, 0xE8, 0xA7, 0x7A,
0x04, 0x9D, 0x4B, 0x05, 0x24, 0xA3, 0x36, 0xAF, 0x3C, 0x18, 0xBC, 0xBA, 0xEF, 0xC8, 0x0B, 0xB9, 0x6E, 0xA8, 0x26, 0x73,
0xFD, 0x11, 0x2A, 0x2F, 0x14, 0xCD, 0x19, 0x63, 0xB6, 0xA8, 0xFC, 0x0B, 0x44, 0x9B, 0x56, 0x21, 0xF1, 0xA8, 0x98, 0xC7,
0x07, 0xCB, 0x82, 0x76, 0x48, 0x89, 0x3F, 0x77, 0x5E, 0xA1, 0xAF, 0xCE, 0x26, 0x48, 0xDE, 0xC2, 0xD2, 0x69, 0x4C, 0xF5,
0x4D, 0x31, 0x2E, 0x46, 0x8C, 0x94, 0x1D, 0x6C, 0x35, 0x95, 0x3B, 0x17, 0x62, 0xB0, 0xE8, 0xF7, 0x1B, 0x34, 0x5A, 0x7F,
0xD7, 0x5B, 0x5F, 0xA2, 0xD4, 0xCC, 0x5A, 0xB2, 0x2D, 0x9A, 0x1A, 0xDD, 0x7A, 0x1E, 0x45, 0x78, 0x9F, 0x8C, 0x3C, 0x5A,
0x6B, 0x22, 0x8B, 0x7E, 0x8C, 0xE8, 0x2C, 0xDD, 0x4F, 0x8E, 0x49, 0xE5, 0xDD, 0x51, 0x2F, 0x46, 0x3A, 0xE2, 0x2F, 0x04,
0x6A, 0xE8, 0xE9, 0x74, 0xAE, 0xF6, 0xCF, 0x9F, 0x32, 0xEF, 0x19, 0xEB, 0xDE, 0x2D, 0xFF, 0xDA, 0xD2, 0x68, 0x98, 0xBB,
0xE0, 0xDA, 0x9A, 0x83, 0x30, 0x81, 0xFF, 0xFC, 0xC2, 0x23, 0x40, 0x55, 0xA3, 0xDC, 0xBB, 0x56, 0x0C, 0x70, 0x25, 0x66,
0x52, 0xEA, 0x78, 0x0E, 0x9E, 0x02, 0xE3, 0x2C, 0xD7, 0xFC, 0x81, 0xC0, 0xB9, 0xE6, 0xAB, 0xA4, 0xC9, 0xBC, 0xD5, 0xE1,
0x6A, 0xA9, 0xB6, 0x6B, 0x73, 0x5E, 0x00, 0x00, 0x00, 0x00
};

/* USER CODE END 0 */

int main(void)
{

  /* MCU Configuration--------------------------------------------------------*/

  /* Reset of all peripherals, Initializes the Flash interface and the Systick. */
  HAL_Init();

  /* Configure the system clock */
  SystemClock_Config();

  /* Initialize all configured peripherals */
  MX_GPIO_Init();
  MX_TIM2_Init();
  MX_TIM21_Init();
  /* USER CODE BEGIN 2 */

  HAL_TIM_OC_Start(&htim21,TIM_CHANNEL_2);
	HAL_TIM_Base_Start_IT(&htim2);

  //  Define time to send one byte
  uint8_t time_per_bit_ms = 1;
  uint16_t time_to_send_one_byte = time_per_bit_ms * 8;

  /* USER CODE END 2 */

  /* Infinite loop */
  while (1)
  {

    /* USER CODE BEGIN 3 */

    //  Use the transmit buffer from flash && Backscatter the data
    tx_send(&bc_handler, code, sizeof(code));

    //  Minimum delay to send buffer again
    HAL_Delay(sizeof(code)*time_to_send_one_byte);

    //  Optional, add additional delay between packet transmissions
    HAL_Delay(5000);
  }
  /* USER CODE END 3 */
}

void SystemClock_Config(void)
{
  RCC_OscInitTypeDef RCC_OscInitStruct = {0};
  RCC_ClkInitTypeDef RCC_ClkInitStruct = {0};

  /** Configure the main internal regulator output voltage
  */
  __HAL_PWR_VOLTAGESCALING_CONFIG(PWR_REGULATOR_VOLTAGE_SCALE1);

  /** Initializes the RCC Oscillators according to the specified parameters
  * in the RCC_OscInitTypeDef structure.
  */
  RCC_OscInitStruct.OscillatorType = RCC_OSCILLATORTYPE_MSI;
  RCC_OscInitStruct.MSIState = RCC_MSI_ON;
  RCC_OscInitStruct.MSICalibrationValue = 0;
  RCC_OscInitStruct.MSIClockRange = RCC_MSIRANGE_4;
  RCC_OscInitStruct.PLL.PLLState = RCC_PLL_NONE;
  if (HAL_RCC_OscConfig(&RCC_OscInitStruct) != HAL_OK)
  {
    Error_Handler();
  }

  /** Initializes the CPU, AHB and APB buses clocks
  */
  RCC_ClkInitStruct.ClockType = RCC_CLOCKTYPE_HCLK|RCC_CLOCKTYPE_SYSCLK
                              |RCC_CLOCKTYPE_PCLK1|RCC_CLOCKTYPE_PCLK2;
  RCC_ClkInitStruct.SYSCLKSource = RCC_SYSCLKSOURCE_MSI;
  RCC_ClkInitStruct.AHBCLKDivider = RCC_SYSCLK_DIV1;
  RCC_ClkInitStruct.APB1CLKDivider = RCC_HCLK_DIV1;
  RCC_ClkInitStruct.APB2CLKDivider = RCC_HCLK_DIV1;

  if (HAL_RCC_ClockConfig(&RCC_ClkInitStruct, FLASH_LATENCY_0) != HAL_OK)
  {
    Error_Handler();
  }
}

static void MX_TIM2_Init(void)
{

  TIM_ClockConfigTypeDef sClockSourceConfig = {0};
  TIM_MasterConfigTypeDef sMasterConfig = {0};

  htim2.Instance = TIM2;
  htim2.Init.Prescaler = 1;
  htim2.Init.CounterMode = TIM_COUNTERMODE_UP;
  htim2.Init.Period = 523;
  htim2.Init.ClockDivision = TIM_CLOCKDIVISION_DIV1;
  htim2.Init.AutoReloadPreload = TIM_AUTORELOAD_PRELOAD_DISABLE;
  if (HAL_TIM_Base_Init(&htim2) != HAL_OK)
  {
    Error_Handler();
  }
  sClockSourceConfig.ClockSource = TIM_CLOCKSOURCE_INTERNAL;
  if (HAL_TIM_ConfigClockSource(&htim2, &sClockSourceConfig) != HAL_OK)
  {
    Error_Handler();
  }
  sMasterConfig.MasterOutputTrigger = TIM_TRGO_RESET;
  sMasterConfig.MasterSlaveMode = TIM_MASTERSLAVEMODE_DISABLE;
  if (HAL_TIMEx_MasterConfigSynchronization(&htim2, &sMasterConfig) != HAL_OK)
  {
    Error_Handler();
  }

}

static void MX_TIM21_Init(void)
{

  TIM_ClockConfigTypeDef sClockSourceConfig = {0};
  TIM_MasterConfigTypeDef sMasterConfig = {0};
  TIM_OC_InitTypeDef sConfigOC = {0};

  htim21.Instance = TIM21;
  htim21.Init.Prescaler = 0;
  htim21.Init.CounterMode = TIM_COUNTERMODE_UP;
  htim21.Init.Period = 1;
  htim21.Init.ClockDivision = TIM_CLOCKDIVISION_DIV1;
  htim21.Init.AutoReloadPreload = TIM_AUTORELOAD_PRELOAD_DISABLE;
  if (HAL_TIM_Base_Init(&htim21) != HAL_OK)
  {
    Error_Handler();
  }
  sClockSourceConfig.ClockSource = TIM_CLOCKSOURCE_INTERNAL;
  if (HAL_TIM_ConfigClockSource(&htim21, &sClockSourceConfig) != HAL_OK)
  {
    Error_Handler();
  }
  if (HAL_TIM_PWM_Init(&htim21) != HAL_OK)
  {
    Error_Handler();
  }
  sMasterConfig.MasterOutputTrigger = TIM_TRGO_RESET;
  sMasterConfig.MasterSlaveMode = TIM_MASTERSLAVEMODE_DISABLE;
  if (HAL_TIMEx_MasterConfigSynchronization(&htim21, &sMasterConfig) != HAL_OK)
  {
    Error_Handler();
  }
  sConfigOC.OCMode = TIM_OCMODE_PWM2;
  sConfigOC.Pulse = 1;
  sConfigOC.OCPolarity = TIM_OCPOLARITY_HIGH;
  sConfigOC.OCFastMode = TIM_OCFAST_DISABLE;
  if (HAL_TIM_PWM_ConfigChannel(&htim21, &sConfigOC, TIM_CHANNEL_2) != HAL_OK)
  {
    Error_Handler();
  }
  HAL_TIM_MspPostInit(&htim21);

}

static void MX_GPIO_Init(void)
{
  GPIO_InitTypeDef GPIO_InitStruct = {0};

  /* GPIO Ports Clock Enable */
  __HAL_RCC_GPIOB_CLK_ENABLE();
  __HAL_RCC_GPIOA_CLK_ENABLE();

  /*Configure GPIO pin Output Level */
  HAL_GPIO_WritePin(LED_GPIO_Port, LED_Pin, GPIO_PIN_RESET);

  /*Configure GPIO pin : LED_Pin */
  GPIO_InitStruct.Pin = LED_Pin;
  GPIO_InitStruct.Mode = GPIO_MODE_OUTPUT_PP;
  GPIO_InitStruct.Pull = GPIO_NOPULL;
  GPIO_InitStruct.Speed = GPIO_SPEED_FREQ_LOW;
  HAL_GPIO_Init(LED_GPIO_Port, &GPIO_InitStruct);

}

/* USER CODE BEGIN 4 */

uint8_t counter = 0;

// Currently trigger at 104,8 Hz
void HAL_TIM_PeriodElapsedCallback(TIM_HandleTypeDef* htim)
{
	if(htim == &htim2){

    if(bc_handler.status == SENDING){

      uint16_t byte_value = bc_handler.buffer[bc_handler.current_byte];
      uint8_t bit_value = (byte_value >> bc_handler.current_bit) & 0x01;
      // printf("Byte %d, Bit %d: %u\n", current_byte, current_bit, bit_value);

      if(bit_value){
        HAL_TIM_OC_Start(&htim21,TIM_CHANNEL_2);
        HAL_GPIO_WritePin(LED_GPIO_Port, LED_Pin, GPIO_PIN_SET);
      }
      else{
        HAL_TIM_OC_Stop(&htim21,TIM_CHANNEL_2);
        HAL_GPIO_WritePin(LED_GPIO_Port, LED_Pin, GPIO_PIN_RESET);
      }

      // Update current_bit for next interrupt
      if (bc_handler.current_bit > 0) {
          bc_handler.current_bit--;
      } else {
        bc_handler.current_bit = 7;
        bc_handler.current_byte++;
        if (bc_handler.current_byte >= bc_handler.num_bytes) {

            //  Reset after reaching end of buffer
            bc_handler.current_byte = 0;

            //  Update status
            bc_handler.status = IDLE;

            //  Disable timer
            HAL_TIM_OC_Stop(&htim21,TIM_CHANNEL_2);
        }
      }
    }
	}
}

/* USER CODE END 4 */

void Error_Handler(void)
{
  __disable_irq();
  while (1)
  {
  }
}
